# MSP430FR2433 register map
Vendor: msp430gen; File version: v0.4.0-8-gde1e0b2
Registers are 16-bit, read-write, reset 0x0 unless marked. A register's access mark holds for its fields unless they carry their own. Offsets are from the block's base; [hi:lo] are bit positions; {n}, {i} and the like mark numbered series.

## WATCHDOG_TIMER
Base 0x000001CC
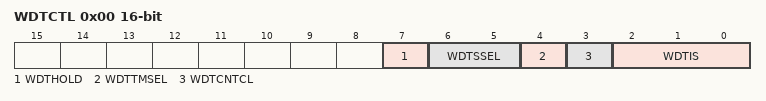
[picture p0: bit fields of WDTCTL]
0x00 WDTCTL — Watchdog Timer Control
  [7] WDTHOLD — WDT - Timer hold
  [6:5] WDTSSEL — WDT - Timer Clock Source Select 0
    0=WDT - Timer Clock Source Select: SMCLK; 1=WDT - Timer Clock Source Select: ACLK; 2=WDT - Timer Clock Source Select: VLO_CLK; 3=WDT - Timer Clock Source Select: reserved
  [4] WDTTMSEL — WDT - Timer Mode Select
  [3] WDTCNTCL — WDT - Timer Clear
  [2:0] WDTIS — WDT - Timer Interval Select 0
    0=WDT - Timer Interval Select: /2G; 1=WDT - Timer Interval Select: /128M; 2=WDT - Timer Interval Select: /8192k; 3=WDT - Timer Interval Select: /512k; 4=WDT - Timer Interval Select: /32k; 5=WDT - Timer Interval Select: /8192; 6=WDT - Timer Interval Select: /512; 7=WDT - Timer Interval Select: /64

## REAL_TIME_CLOCK
Base 0x00000300
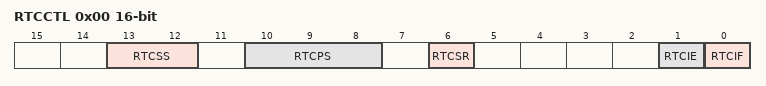
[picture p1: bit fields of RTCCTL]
0x00 RTCCTL — RTC control Register
  [13:12] RTCSS — Low-Power-Counter Clock Source Select Bit: 0
    {v}=Low-Power-Counter Clock Source Select: {v} (v=0..3)
  [10:8] RTCPS — Low-Power-Counter Clock Pre-divider Select Bit: 0
    {v}=Low-Power-Counter Clock Pre-divider Select: {v} (v=0..7)
  [6] RTCSR — Low-Power-Counter Software Reset
  [1] RTCIE — Low-Power-Counter Interrupt Enable
  [0] RTCIF — Low-Power-Counter Interrupt Flag
0x04 RTCIV — RTC interrupt vector
0x08 RTCMOD — RTC moduloRegister
0x0C RTCCNT — RTC counter Register

## TIMER_0_A3
Base 0x00000380
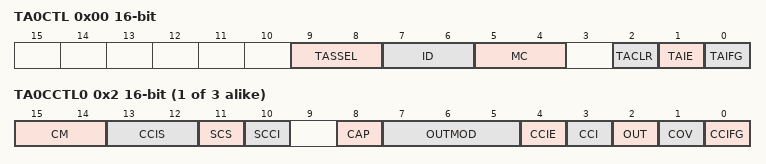
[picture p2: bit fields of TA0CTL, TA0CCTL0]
0x00 TA0CTL — Timer0_A3 Control
  [9:8] TASSEL — Timer A clock source select 1
    0=Timer A clock source select: 0 - TACLK; 1=Timer A clock source select: 1 - ACLK; 2=Timer A clock source select: 2 - SMCLK; 3=Timer A clock source select: 3 - INCLK
  [7:6] ID — Timer A clock input divider 1
    0=Timer A input divider: 0 - /1; 1=Timer A input divider: 1 - /2; 2=Timer A input divider: 2 - /4; 3=Timer A input divider: 3 - /8
  [5:4] MC — Timer A mode control 1
    0=Timer A mode control: 0 - Stop; 1=Timer A mode control: 1 - Up to CCR0; 2=Timer A mode control: 2 - Continuous up; 3=Timer A mode control: 3 - Up/Down
  [2] TACLR — Timer A counter clear
  [1] TAIE — Timer A counter interrupt enable
  [0] TAIFG — Timer A counter interrupt flag
{0x2+2i} TA0CCTL{i} (i=0..2) — Timer0_A3 Capture/Compare Control {i}
  [15:14] CM — Capture mode 1
    0=Capture mode: 0 - disabled; 1=Capture mode: 1 - pos. edge; 2=Capture mode: 1 - neg. edge; 3=Capture mode: 1 - both edges
  [13:12] CCIS — Capture input select 1
    0=Capture input select: 0 - CCIxA; 1=Capture input select: 1 - CCIxB; 2=Capture input select: 2 - GND; 3=Capture input select: 3 - Vcc
  [11] SCS — Capture sychronize
  [10] SCCI — Latched capture signal (read)
  [8] CAP — Capture mode: 1 /Compare mode : 0
  [7:5] OUTMOD — Output mode 2
    0=PWM output mode: 0 - output only; 1=PWM output mode: 1 - set; 2=PWM output mode: 2 - PWM toggle/reset; 3=PWM output mode: 3 - PWM set/reset; 4=PWM output mode: 4 - toggle; 5=PWM output mode: 5 - Reset; 6=PWM output mode: 6 - PWM toggle/set; 7=PWM output mode: 7 - PWM reset/set
  [4] CCIE — Capture/compare interrupt enable
  [3] CCI — Capture input signal (read)
  [2] OUT — PWM Output signal if output mode 0
  [1] COV — Capture/compare overflow flag
  [0] CCIFG — Capture/compare interrupt flag
0x10 TA0R — Timer0_A3
{0x12+2i} TA0CCR{i} (i=0..2) — Timer0_A3 Capture/Compare {i}
0x20 TA0EX0 — Timer0_A3 Expansion Register 0
  [2:0] TAIDEX — Timer A Input divider expansion Bit: 0
    {v}=Timer A Input divider expansion : /{v+1} (v=0..7)
0x2E TA0IV — Timer0_A3 Interrupt Vector Word

## TIMER_1_A3
Base 0x000003C0
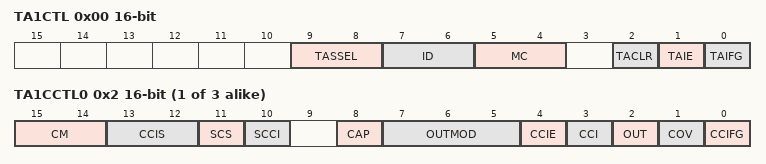
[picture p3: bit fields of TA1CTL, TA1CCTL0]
0x00 TA1CTL — Timer1_A3 Control
  [9:8] TASSEL — Timer A clock source select 1
    0=Timer A clock source select: 0 - TACLK; 1=Timer A clock source select: 1 - ACLK; 2=Timer A clock source select: 2 - SMCLK; 3=Timer A clock source select: 3 - INCLK
  [7:6] ID — Timer A clock input divider 1
    0=Timer A input divider: 0 - /1; 1=Timer A input divider: 1 - /2; 2=Timer A input divider: 2 - /4; 3=Timer A input divider: 3 - /8
  [5:4] MC — Timer A mode control 1
    0=Timer A mode control: 0 - Stop; 1=Timer A mode control: 1 - Up to CCR0; 2=Timer A mode control: 2 - Continuous up; 3=Timer A mode control: 3 - Up/Down
  [2] TACLR — Timer A counter clear
  [1] TAIE — Timer A counter interrupt enable
  [0] TAIFG — Timer A counter interrupt flag
{0x2+2i} TA1CCTL{i} (i=0..2) — Timer1_A3 Capture/Compare Control {i}
  [15:14] CM — Capture mode 1
    0=Capture mode: 0 - disabled; 1=Capture mode: 1 - pos. edge; 2=Capture mode: 1 - neg. edge; 3=Capture mode: 1 - both edges
  [13:12] CCIS — Capture input select 1
    0=Capture input select: 0 - CCIxA; 1=Capture input select: 1 - CCIxB; 2=Capture input select: 2 - GND; 3=Capture input select: 3 - Vcc
  [11] SCS — Capture sychronize
  [10] SCCI — Latched capture signal (read)
  [8] CAP — Capture mode: 1 /Compare mode : 0
  [7:5] OUTMOD — Output mode 2
    0=PWM output mode: 0 - output only; 1=PWM output mode: 1 - set; 2=PWM output mode: 2 - PWM toggle/reset; 3=PWM output mode: 3 - PWM set/reset; 4=PWM output mode: 4 - toggle; 5=PWM output mode: 5 - Reset; 6=PWM output mode: 6 - PWM toggle/set; 7=PWM output mode: 7 - PWM reset/set
  [4] CCIE — Capture/compare interrupt enable
  [3] CCI — Capture input signal (read)
  [2] OUT — PWM Output signal if output mode 0
  [1] COV — Capture/compare overflow flag
  [0] CCIFG — Capture/compare interrupt flag
0x10 TA1R — Timer1_A3
{0x12+2i} TA1CCR{i} (i=0..2) — Timer1_A3 Capture/Compare {i}
0x20 TA1EX0 — Timer1_A3 Expansion Register 0
  [2:0] TAIDEX — Timer A Input divider expansion Bit: 0
    {v}=Timer A Input divider expansion : /{v+1} (v=0..7)
0x2E TA1IV — Timer1_A3 Interrupt Vector Word
